# STM32MP153x register map
File version: 1.0
Registers are 32-bit, read-write, reset 0x0 unless marked. A register's access mark holds for its fields unless they carry their own. Offsets are from the block's base; [hi:lo] are bit positions; {n}, {i} and the like mark numbered series.

## GICC
Base 0xA0022000
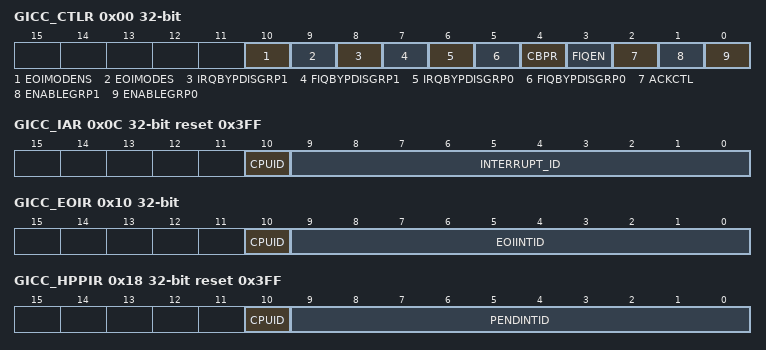
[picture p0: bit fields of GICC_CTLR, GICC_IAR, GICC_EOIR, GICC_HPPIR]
0x00 GICC_CTLR — GICC control register
  [10] EOIMODENS, [9] EOIMODES, [8] IRQBYPDISGRP1, [7] FIQBYPDISGRP1, [6] IRQBYPDISGRP0, [5] FIQBYPDISGRP0, [4] CBPR, [3] FIQEN, [2] ACKCTL, [1] ENABLEGRP1, [0] ENABLEGRP0
0x04 GICC_PMR — GICC input priority mask register
  [7:3] PRIORITY
0x08 GICC_BPR reset 0x2 — GICC binary point register
  [2:0] BINARY_POINT
0x0C GICC_IAR ro reset 0x3FF — GICC interrupt acknowledge register
  [10] CPUID, [9:0] INTERRUPT_ID
0x10 GICC_EOIR wo — GICC end of interrupt register
  [10] CPUID, [9:0] EOIINTID
0x14 GICC_RPR ro reset 0xFF — GICC running priority register
  [7:3] PRIORITY
0x18 GICC_HPPIR ro reset 0x3FF — GICC highest priority pending interrupt register
  [10] CPUID, [9:0] PENDINTID
0x1C GICC_ABPR reset 0x3 — GICC_ABPR is an alias of the non-secure GICC_BPR. When GICC_CTLR.CBPR is set to 0, a secure access to this register is equivalent to a non-secure access to GICC_BPR.
  [2:0] BINARY_POINT
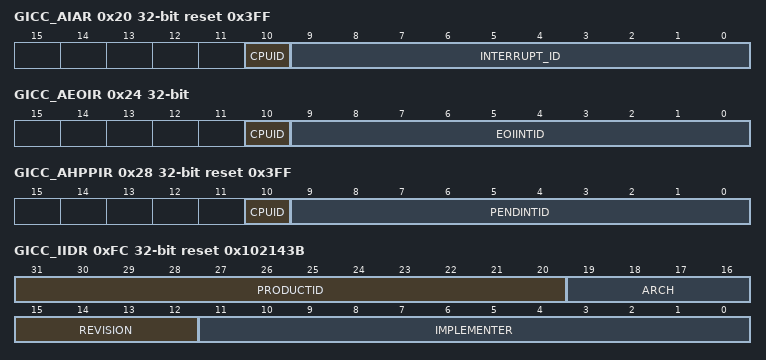
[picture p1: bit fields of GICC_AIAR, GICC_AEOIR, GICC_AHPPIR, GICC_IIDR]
0x20 GICC_AIAR ro reset 0x3FF — GICC_AIAR is an alias of the non-secure view of GICC_IAR. A secure access to this register is identical to a non-secure access to GICC_IAR.
  [10] CPUID, [9:0] INTERRUPT_ID
0x24 GICC_AEOIR wo — GICC_AEOIR is an alias of the Non-secure GICC_EOIR. A secure access to this register is similar to a non-secure access to GICC_EOIR, except that the GICC_CTLR.EOImodeS bit is used.
  [10] CPUID, [9:0] EOIINTID
0x28 GICC_AHPPIR ro reset 0x3FF — ICC_AHPPIR is an alias of the non-secure GICC_HPPIR. A secure access to this register is equivalent to a non-secure access to GICC_HPPIR.
  [10] CPUID, [9:0] PENDINTID
0xD0 GICC_APR0 — GICC active priority register
0xE0 GICC_NSAPR0 — GICC non-secure active priority register
0xFC GICC_IIDR ro reset 0x102143B — GICC interface identification register
  [31:20] PRODUCTID, [19:16] ARCH, [15:12] REVISION, [11:0] IMPLEMENTER
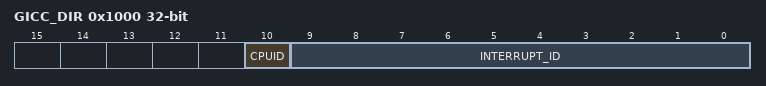
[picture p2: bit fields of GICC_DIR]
0x1000 GICC_DIR wo — GICC deactivate interrupt register
  [10] CPUID, [9:0] INTERRUPT_ID

## GICH
Base 0xA0024000
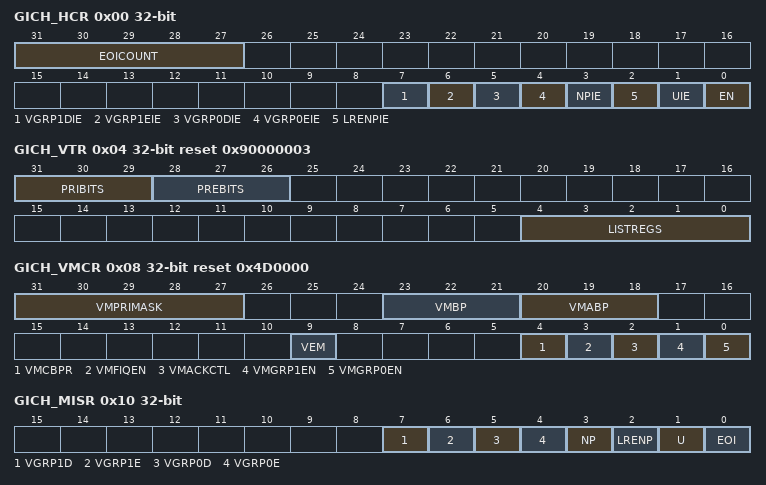
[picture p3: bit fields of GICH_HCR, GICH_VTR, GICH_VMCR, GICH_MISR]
0x00 GICH_HCR — GICH hypervisor control register
  [31:27] EOICOUNT, [7] VGRP1DIE, [6] VGRP1EIE, [5] VGRP0DIE, [4] VGRP0EIE, [3] NPIE, [2] LRENPIE, [1] UIE, [0] EN
0x04 GICH_VTR ro reset 0x90000003 — GICH VGIC type register
  [31:29] PRIBITS, [28:26] PREBITS, [4:0] LISTREGS
0x08 GICH_VMCR reset 0x4D0000 — GICH virtual machine control register
  [31:27] VMPRIMASK, [23:21] VMBP, [20:18] VMABP, [9] VEM, [4] VMCBPR, [3] VMFIQEN, [2] VMACKCTL, [1] VMGRP1EN, [0] VMGRP0EN
0x10 GICH_MISR ro — GICH maintenance interrupt status register
  [7] VGRP1D, [6] VGRP1E, [5] VGRP0D, [4] VGRP0E, [3] NP, [2] LRENP, [1] U, [0] EOI
0x20 GICH_EISR0 ro — GICH end of interrupt status register
0x30 GICH_ELSR0 ro reset 0xF — GICH empty list status register
0xF0 GICH_APR0 — GICH active priority register
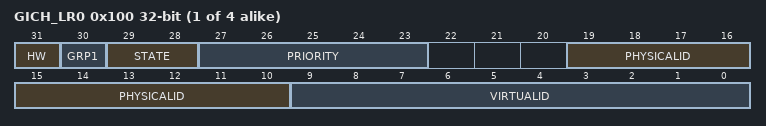
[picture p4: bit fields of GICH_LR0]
{0x100+4i} GICH_LR{i} (i=0..3) — GICH list register {i}
  [31] HW, [30] GRP1, [29:28] STATE, [27:23] PRIORITY, [19:10] PHYSICALID, [9:0] VIRTUALID

## GICV
Base 0xA0026000
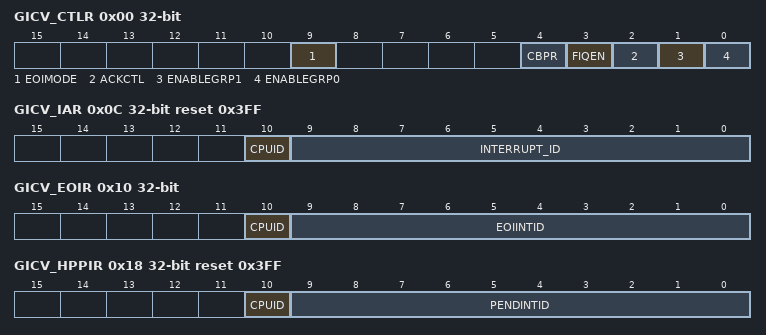
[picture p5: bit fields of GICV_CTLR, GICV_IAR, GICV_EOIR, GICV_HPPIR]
0x00 GICV_CTLR — GICV virtual machine control register
  [9] EOIMODE, [4] CBPR, [3] FIQEN, [2] ACKCTL, [1] ENABLEGRP1, [0] ENABLEGRP0
0x04 GICV_PMR — GICV VM priority mask register
  [7:3] PRIORITY
0x08 GICV_BPR reset 0x2 — GICV VM binary point register
  [2:0] BINARY_POINT
0x0C GICV_IAR ro reset 0x3FF — GICV VM interrupt acknowledge register
  [10] CPUID, [9:0] INTERRUPT_ID
0x10 GICV_EOIR wo — GICV VM end of interrupt register
  [10] CPUID, [9:0] EOIINTID
0x14 GICV_RPR ro reset 0xFF — GICV VM running priority register
  [7:3] PRIORITY
0x18 GICV_HPPIR ro reset 0x3FF — GICV VM highest priority pending interrupt register
  [10] CPUID, [9:0] PENDINTID
0x1C GICV_ABPR reset 0x3 — GICV VM aliased binary point register
  [2:0] BINARY_POINT
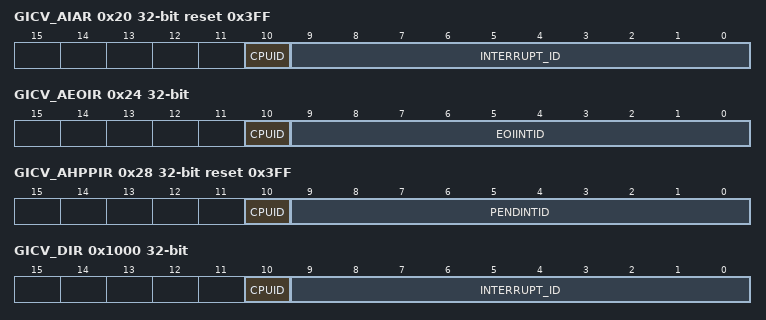
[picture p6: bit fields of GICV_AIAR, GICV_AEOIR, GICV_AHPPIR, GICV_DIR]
0x20 GICV_AIAR ro reset 0x3FF — GICV VM aliased interrupt register
  [10] CPUID, [9:0] INTERRUPT_ID
0x24 GICV_AEOIR wo — GICV VM aliased end of interrupt register
  [10] CPUID, [9:0] EOIINTID
0x28 GICV_AHPPIR ro reset 0x3FF — GICV VM aliased highest priority pending interrupt register
  [10] CPUID, [9:0] PENDINTID
0xD0 GICV_APR0 — The GICV_APR0 is an alias of GICH_APR.
0xFC GICV_IIDR ro reset 0x102143B — The GICV_IIDR is an alias of GICC_IIDR.
0x1000 GICV_DIR wo — GICV VM deactivate interrupt register
  [10] CPUID, [9:0] INTERRUPT_ID
